# sam67_dmpac_wrap0_DMPAC_TOP_CFG_SLV_DMPAC_FOCO_0_CFG_SLV_VPAC_FOCO_LSE_CFG_VP register map
Vendor: Texas Instruments
Peripheral module from a debugger description file (folder J722S).
Registers are 32-bit, access per field, reset values left out (the file's numbers can be read two ways) unless marked. A register's access mark holds for its fields unless they carry their own. Offsets are as the file gives them; lines under a group give offsets from that group; [hi:lo] are bit positions; {n}, {i} and the like mark numbered series; 'fields as' and 'values as' point back to an identical list; <NAME> marks a mode.

## sam67_dmpac_wrap0_DMPAC_TOP_CFG_SLV_DMPAC_FOCO_0_CFG_SLV_VPAC_FOCO_LSE_CFG_VP
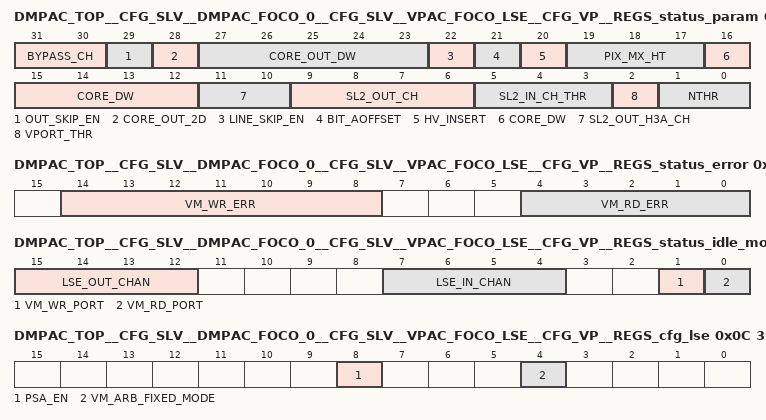
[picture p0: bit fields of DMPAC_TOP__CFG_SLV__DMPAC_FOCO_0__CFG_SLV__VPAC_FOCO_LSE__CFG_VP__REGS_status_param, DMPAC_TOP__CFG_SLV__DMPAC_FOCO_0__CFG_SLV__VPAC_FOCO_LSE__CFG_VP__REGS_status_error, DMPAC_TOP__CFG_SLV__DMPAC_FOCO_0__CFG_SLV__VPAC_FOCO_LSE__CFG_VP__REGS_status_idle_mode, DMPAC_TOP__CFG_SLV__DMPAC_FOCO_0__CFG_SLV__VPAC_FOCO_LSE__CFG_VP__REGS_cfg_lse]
0x00 DMPAC_TOP__CFG_SLV__DMPAC_FOCO_0__CFG_SLV__VPAC_FOCO_LSE__CFG_VP__REGS_status_param ro — The STATUS_PARAM register returns the LSE compile configuration parameters.
  [31:30] BYPASS_CH — Number of available input channel selection for loopback mode
  [29] OUT_SKIP_EN — Output Auto-Skip Enable
  [28] CORE_OUT_2D — 1D or 2D output addressing mode(2D if 1)
  [27:23] CORE_OUT_DW — Core Output Channel Data Width
  [22] LINE_SKIP_EN — Source Line Inc by 2 Supported (if 1)
  [21] BIT_AOFFSET — Source nibble offset address Supported (if 1)
  [20] HV_INSERT — H/VBLANK Insertion Supported (if 1)
  [19:17] PIX_MX_HT — Core_Input Pixel Matrix Height
  [16:12] CORE_DW — Core Input Data Bus Width
  [11:10] SL2_OUT_H3A_CH — Number of SL2 H3A Output Channels
  [9:6] SL2_OUT_CH — Number of SL2 Output Channels
  [5:3] SL2_IN_CH_THR — Number of Input Channels per thread
  [2] VPORT_THR — Number of VPORT input enabled
  [1:0] NTHR — Number of threads supported
0x04 DMPAC_TOP__CFG_SLV__DMPAC_FOCO_0__CFG_SLV__VPAC_FOCO_LSE__CFG_VP__REGS_status_error access not given — The STATUS_ERROR register returns the LSE error status.
  [14:8] VM_WR_ERR — VBUSM I/F Last Write Error Status [14:11] Write Channel Number [10:8] VBUSM write error status (access R/W1TC)
  [4:0] VM_RD_ERR — VBUSM I/F Last Read Error Status [4:3] Read Channel Number [2:0] VBUSM read error status (access R/W1TC)
0x08 DMPAC_TOP__CFG_SLV__DMPAC_FOCO_0__CFG_SLV__VPAC_FOCO_LSE__CFG_VP__REGS_status_idle_mode ro — The STATUS_IDLE_MODE register returns IDLE status of LSE VBUSM port and in/output channels - 0: IDLE 1: ACTIVE
  [15:12] LSE_OUT_CHAN — Output Channel[3:0] Status
  [7:4] LSE_IN_CHAN — Input Channel[3:0] Status
  [1] VM_WR_PORT — SL2 vbusm I/F Write Port Status
  [0] VM_RD_PORT — SL2 vbusm I/F Read Port Status
0x0C DMPAC_TOP__CFG_SLV__DMPAC_FOCO_0__CFG_SLV__VPAC_FOCO_LSE__CFG_VP__REGS_cfg_lse rw — The CFG_LSE register configures the LSE general hardware modes.
  [8] PSA_EN — Test mode Output Channel Signature Generation Enable 0: Disable (default) 1: Enable When enabled, LSE generates a unique CRC signature for each output channel's frame data at frame completion.
  [4] VM_ARB_FIXED_MODE — VBUSM Arbitration Fixed Mode select 0: Round-Robin Arbitration (default) 1: Fixed-mode Arbitration
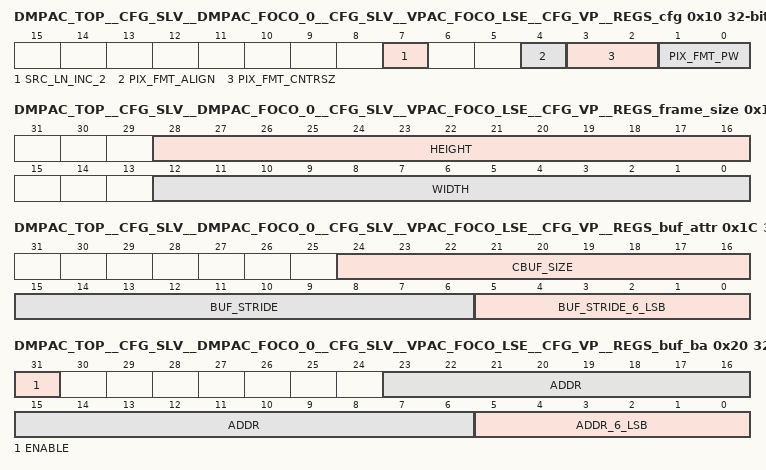
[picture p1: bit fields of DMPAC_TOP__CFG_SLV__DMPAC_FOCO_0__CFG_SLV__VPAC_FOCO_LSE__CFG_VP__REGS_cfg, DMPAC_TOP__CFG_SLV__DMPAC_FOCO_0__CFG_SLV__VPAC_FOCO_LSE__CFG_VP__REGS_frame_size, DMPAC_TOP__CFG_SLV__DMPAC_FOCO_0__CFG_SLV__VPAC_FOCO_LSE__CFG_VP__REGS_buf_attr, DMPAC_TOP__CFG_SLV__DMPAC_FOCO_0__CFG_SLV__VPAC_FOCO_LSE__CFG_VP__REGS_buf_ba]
0x10 DMPAC_TOP__CFG_SLV__DMPAC_FOCO_0__CFG_SLV__VPAC_FOCO_LSE__CFG_VP__REGS_cfg rw — The SRC_CFG register configures the input channels for the processing thread
  [7] SRC_LN_INC_2 — Source Line address Increment by 2 enable 0: Disable 1: Enable
  [4] PIX_FMT_ALIGN — Input Pixel Container Alignment 0: LSB-aligned 1: MSB-aligned
  [3:2] PIX_FMT_CNTRSZ — Input Pixel Container Size Sel 0: 8-bit 1: 12-bit 2: 16-bit 3: reserved Input pixel container size must be same or larger than input pixel width.
  [1:0] PIX_FMT_PW — Input Pixel Width Sel 0: 8-bit 1: 12-bit 2: 14-bit 3: 16-bit The width defines the bit-depth of the pixel data to be extracted from the pixel container.
0x18 DMPAC_TOP__CFG_SLV__DMPAC_FOCO_0__CFG_SLV__VPAC_FOCO_LSE__CFG_VP__REGS_frame_size rw — The SRC_FRAME_SIZE register configures the frame size of all input buffers for the processing thread .
  [28:16] HEIGHT — SL2 - Source Buffer Height (number of lines)
  [12:0] WIDTH — SL2 - Source Buffer Width (number of pixels)
0x1C DMPAC_TOP__CFG_SLV__DMPAC_FOCO_0__CFG_SLV__VPAC_FOCO_LSE__CFG_VP__REGS_buf_attr — The SRC_BUF_ATTR register configures the common attributes of all SL2 source buffers for the processing thread .
  [24:16] CBUF_SIZE rw — SL2 Circular Buffer Size (number of line buffers)
  [15:6] BUF_STRIDE rw — Buffer Stride Size [15:6] (64 byte multiple) stride size
  [5:0] BUF_STRIDE_6_LSB ro — Buffer Stride Size [5:0] - 6 LSB bits of buffer stride size should always be 0. Writes have no effect. Always read as 0
0x20 DMPAC_TOP__CFG_SLV__DMPAC_FOCO_0__CFG_SLV__VPAC_FOCO_LSE__CFG_VP__REGS_buf_ba — The SRC_BUF_BA[b] register configures the base address of the SL2 source buffer [b] for the processing thread .
  [31] ENABLE rw — Input Buffer Enable 0: Disable 1: Enable When the processing thread is enabled, at least one of the input buffer must be enabled
  [23:6] ADDR rw — Base Address[23:6] - (64 Byte aligned) byte address
  [5:0] ADDR_6_LSB ro — Base Address[5:0] - 6 LSB bits of address should always be 0. Writes have no effect. Always read as 0
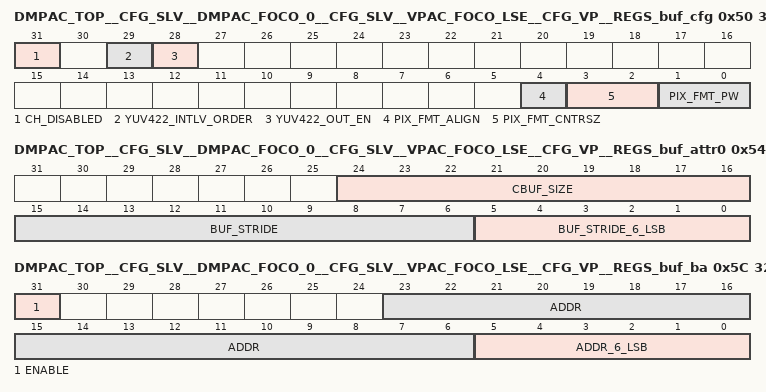
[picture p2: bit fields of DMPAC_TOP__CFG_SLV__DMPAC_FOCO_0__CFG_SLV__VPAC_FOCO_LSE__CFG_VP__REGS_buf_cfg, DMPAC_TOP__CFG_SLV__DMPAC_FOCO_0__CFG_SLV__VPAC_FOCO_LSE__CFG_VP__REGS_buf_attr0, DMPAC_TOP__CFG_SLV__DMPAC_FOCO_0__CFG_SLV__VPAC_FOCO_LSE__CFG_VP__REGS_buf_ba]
0x50 DMPAC_TOP__CFG_SLV__DMPAC_FOCO_0__CFG_SLV__VPAC_FOCO_LSE__CFG_VP__REGS_buf_cfg — The DST_BUF_CFG register configures the output buffer channel .
  [31] CH_DISABLED ro — Channel Disable Status (read-only) 0: (Default) Chanel is enabled for Y, UV or YUV422 data transfer to SL2 memory. All configurations associated with this DST_BUF[a] are valid. 1: Channel is disabled for SL2 data transfer (because the channel logic is used internally for YUV data interleaving). All configuration associated with this DST_BUF[a] are ignored.
  [29] YUV422_INTLV_ORDER rw — YUV422 Interleaving Order Selection 0: UYVY 1: YUYV Only Applicable if this output channel is YUV422 output capable LUMA channel. Otherwise, setting has no effect.
  [28] YUV422_OUT_EN rw — YUV422 Interleaved Output Merge Enable 0: Disable 1: Enable When enabled, this channel interleaves data from the associated chroma data output channel to output YUV422 interleaved data to the SL2 memory. Only Applicable if this output channel is YUV422 output capable LUMA channel. Otherwise, setting has no effect.
  [4] PIX_FMT_ALIGN rw — Output Pixel Container Alignment 0: LSB-aligned 1: MSB-aligned
  [3:2] PIX_FMT_CNTRSZ rw — Output Pixel Container Size Sel 0: 8-bit 1: 12-bit 2: 16-bit 3: reserved Output pixel container size must be same or larger than output pixel width. If yuv422_out_en is set, pix_fmt_cntrsz must be 0.
  [1:0] PIX_FMT_PW rw — Output Pixel Width Sel 0: 8-bit 1: 12-bit 2: reserved 3: 16-bit The width defines the bit-depth of the pixel data to be stored in the pixel container.
0x54 DMPAC_TOP__CFG_SLV__DMPAC_FOCO_0__CFG_SLV__VPAC_FOCO_LSE__CFG_VP__REGS_buf_attr0 — The DST_BUF_ATTR0 register configures the attributes of the output SL2 buffer .
  fields as DMPAC_TOP__CFG_SLV__DMPAC_FOCO_0__CFG_SLV__VPAC_FOCO_LSE__CFG_VP__REGS_buf_attr
0x5C DMPAC_TOP__CFG_SLV__DMPAC_FOCO_0__CFG_SLV__VPAC_FOCO_LSE__CFG_VP__REGS_buf_ba — The DST_BUF_BA register configures the base address of the output SL2 circular buffer .
  [31] ENABLE rw — Output Channel Enable 0: Disable 1: Enable
  [23:6] ADDR rw — Base Address[23:6] - (64 Byte aligned) byte address
  [5:0] ADDR_6_LSB ro — Base Address[5:0] - 6 LSB bits of address should always be 0. Writes have no effect. Always read as 0
0x140 DMPAC_TOP__CFG_SLV__DMPAC_FOCO_0__CFG_SLV__VPAC_FOCO_LSE__CFG_VP__REGS_psa_signature ro — The PSA_SIGNATURE register returns the captured PSA signature value of the last frame data of output channel [a].
  [31:0] VALUE — 32-bit CRC signature value
0x1E0 DMPAC_TOP__CFG_SLV__DMPAC_FOCO_0__CFG_SLV__VPAC_FOCO_LSE__CFG_VP__REGS_dbg ro — The DBG register returns the current status of internal FSM - TI internal use only.
  [31:0] STATUS — Debug status
